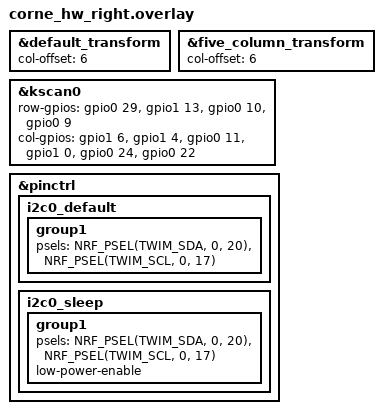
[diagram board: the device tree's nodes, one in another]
/*
 * Copyright (c) 2020 The ZMK Contributors
 *
 * SPDX-License-Identifier: MIT
 */

#include <dt-bindings/pinctrl/nrf-pinctrl.h>
#include "corne_hw.dtsi"

&default_transform {
    col-offset = <6>;
};

&five_column_transform {
    col-offset = <6>;
};

&kscan0 {
    row-gpios = <&gpio0 29 (GPIO_ACTIVE_HIGH | GPIO_PULL_DOWN)>,  /* Row 0 = P0.29 */
                <&gpio1 13 (GPIO_ACTIVE_HIGH | GPIO_PULL_DOWN)>,  /* Row 1 = P1.13 */
                <&gpio0 10 (GPIO_ACTIVE_HIGH | GPIO_PULL_DOWN)>,  /* Row 2 = P0.10 */
                <&gpio0 9  (GPIO_ACTIVE_HIGH | GPIO_PULL_DOWN)>;  /* Row 3 = P0.09 */

    col-gpios = <&gpio1 6  GPIO_ACTIVE_HIGH>,  /* Col 0 = P1.06 */
                <&gpio1 4  GPIO_ACTIVE_HIGH>,  /* Col 1 = P1.04 */
                <&gpio0 11 GPIO_ACTIVE_HIGH>,  /* Col 2 = P0.11 */
                <&gpio1 0  GPIO_ACTIVE_HIGH>,  /* Col 3 = P1.00 */
                <&gpio0 24 GPIO_ACTIVE_HIGH>,  /* Col 4 = P0.24 */
                <&gpio0 22 GPIO_ACTIVE_HIGH>;  /* Col 5 = P0.22 */
};

// Override I2C pinctrl for custom OLED wiring  
// User wiring: SDA=017, SCL=020 -> SDA=P0.20, SCL=P0.17
&pinctrl {
    i2c0_default: i2c0_default {
        group1 {
            psels = <NRF_PSEL(TWIM_SDA, 0, 20)>,  /* SDA = P0.20 */
                    <NRF_PSEL(TWIM_SCL, 0, 17)>;  /* SCL = P0.17 */
        };
    };

    i2c0_sleep: i2c0_sleep {
        group1 {
            psels = <NRF_PSEL(TWIM_SDA, 0, 20)>,  /* SDA = P0.20 */
                    <NRF_PSEL(TWIM_SCL, 0, 17)>;  /* SCL = P0.17 */
            low-power-enable;
        };
    };
};

